# ATSAML21J18BU register map
Vendor: Microchip Technology; Series: SAML21; File version: 0
CPU: CM0+ r0p0, selectable endian, no MPU, no FPU, 2 interrupt priority bits
Registers are 32-bit, read-write, reset 0x0 unless marked. A register's access mark holds for its fields unless they carry their own. Offsets are from the block's base; [hi:lo] are bit positions; {n}, {i} and the like mark numbered series; 'fields as' and 'values as' point back to an identical list.

## MTB — Cortex-M0+ Micro-Trace Buffer
Base 0x41006000; register names take the prefix MTB_
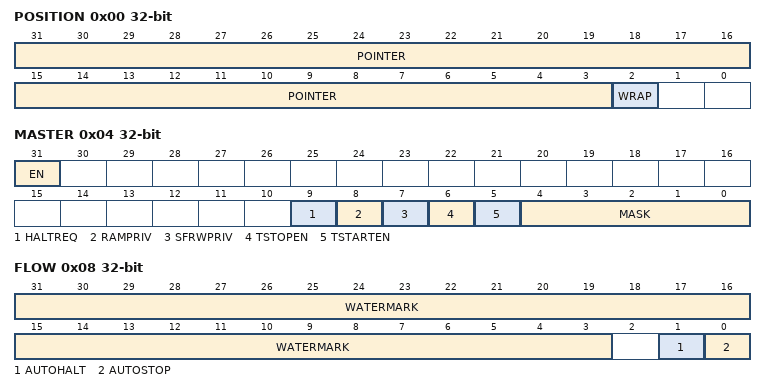
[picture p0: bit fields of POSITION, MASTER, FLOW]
0x00 POSITION — MTB Position
  [31:3] POINTER — Trace Packet Location Pointer
  [2] WRAP — Pointer Value Wraps
0x04 MASTER — MTB Master
  [31] EN — Main Trace Enable
  [9] HALTREQ — Halt Request
  [8] RAMPRIV — SRAM Privilege
  [7] SFRWPRIV — Special Function Register Write Privilege
  [6] TSTOPEN — Trace Stop Input Enable
  [5] TSTARTEN — Trace Start Input Enable
  [4:0] MASK — Maximum Value of the Trace Buffer in SRAM
0x08 FLOW — MTB Flow
  [31:3] WATERMARK — Watermark value
  [1] AUTOHALT — Auto Halt Request
  [0] AUTOSTOP — Auto Stop Tracing
0x0C BASE ro — MTB Base
0xF00 ITCTRL — MTB Integration Mode Control
0xFA0 CLAIMSET — MTB Claim Set
0xFA4 CLAIMCLR — MTB Claim Clear
0xFB0 LOCKACCESS — MTB Lock Access
0xFB4 LOCKSTATUS ro — MTB Lock Status
0xFB8 AUTHSTATUS ro — MTB Authentication Status
0xFBC DEVARCH ro — MTB Device Architecture
0xFC8 DEVID ro — MTB Device Configuration
0xFCC DEVTYPE ro — MTB Device Type
{0xFC0+4i} PID{i} ro (i=4..7) — Peripheral Identification {i}
{0xFE0+4i} PID{i} ro (i=0..3) — Peripheral Identification {i}
{0xFF0+4i} CID{i} ro (i=0..3) — Component Identification {i}

## OPAMP — Operational Amplifier
Base 0x43001800; register names take the prefix OPAMP_
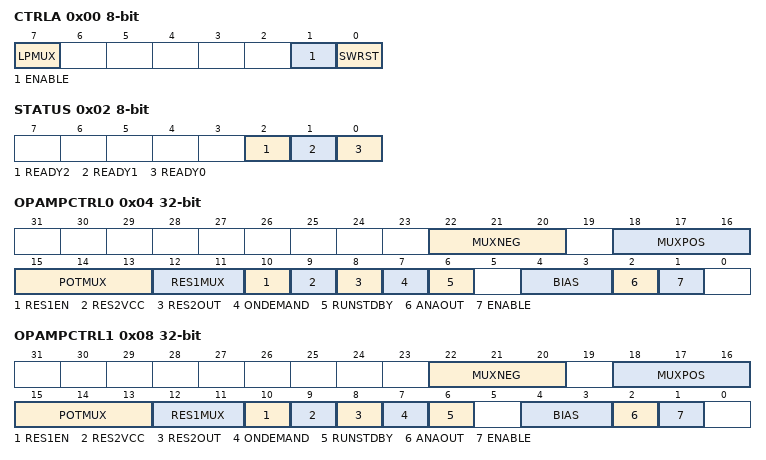
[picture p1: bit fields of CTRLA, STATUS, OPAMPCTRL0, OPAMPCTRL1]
0x00 CTRLA 8-bit — Control A
  [7] LPMUX — Low-Power Mux
  [1] ENABLE
  [0] SWRST — Software Reset
0x02 STATUS 8-bit ro
  [2] READY2 — OPAMP 2 Ready
  [1] READY1 — OPAMP 1 Ready
  [0] READY0 — OPAMP 0 Ready
0x04 OPAMPCTRL0 — OPAMP0 Control
  [22:20] MUXNEG — Negative Input Mux Selection
    0=OA0NEG (Negative I/O pin); 1=OA0TAP (Resistor ladder 0 taps); 2=OA0OUT (OPAMP0 output); 3=DAC (DAC output)
  [18:16] MUXPOS — Positive Input Mux Selection
    0=OA0POS (Positive I/O pin); 1=OA0TAP (Resistor ladder 0 taps); 2=DAC (DAC output); 3=GND (Ground)
  [15:13] POTMUX — Potentiometer Selection
    0=14R_2R (Gain = 0.14); 1=12R_4R (Gain = 0.33); 2=8R_8R (Gain = 1); 3=6R_10R (Gain = 1.67); 4=4R_12R (Gain = 3); 5=3R_13R (Gain = 4.33); 6=2R_14R (Gain = 7); 7=R_15R (Gain = 15)
  [12:11] RES1MUX — Resistor 1 Mux
    0=OAxPOS (Positive inout of OPAMPx); 1=OAxNEG (Negative input of OPAMPx); 2=DAC (DAC output); 3=GND (Ground)
  [10] RES1EN — Resistor 1 Enable
  [9] RES2VCC — Resistor ladder To VCC
  [8] RES2OUT — Resistor ladder To Output
  [7] ONDEMAND — On Demand Control
  [6] RUNSTDBY — Run in Standby
  [4:3] BIAS — Bias Selection
    0=MODE0 (Minimum current consumption, but the slowest mode); 1=MODE1 (Low current consumption, slow speed); 2=MODE2 (High current consumption, fast speed); 3=MODE3 (Maximum current consumption but the fastest mode)
  [2] ANAOUT — Analog Output
  [1] ENABLE — Operational Amplifier Enable
0x08 OPAMPCTRL1 — OPAMP1 Control
  [22:20] MUXNEG — Negative Input Mux Selection
    0=OA1NEG (Negative I/O pin); 1=OA1TAP (Resistor ladder 1 taps); 2=OA1OUT (OPAMP1 output); 3=DAC (DAC output)
  [18:16] MUXPOS — Positive Input Mux Selection
    0=OA1POS (Positive I/O pin); 1=OA1TAP (Resistor ladder 1 taps); 2=OA0OUT (OPAMP0 output); 3=GND (Ground)
  [15:13] POTMUX — Potentiometer Selection
    values as OPAMPCTRL0.POTMUX
  [12:11] RES1MUX — Resistor 1 Mux
    values as OPAMPCTRL0.RES1MUX
  [10] RES1EN — Resistor 1 Enable
  [9] RES2VCC — Resistor ladder To VCC
  [8] RES2OUT — Resistor ladder To Output
  [7] ONDEMAND — On Demand Control
  [6] RUNSTDBY — Run in Standby
  [4:3] BIAS — Bias Selection
    values as OPAMPCTRL0.BIAS
  [2] ANAOUT — Analog Output
  [1] ENABLE — Operational Amplifier Enable
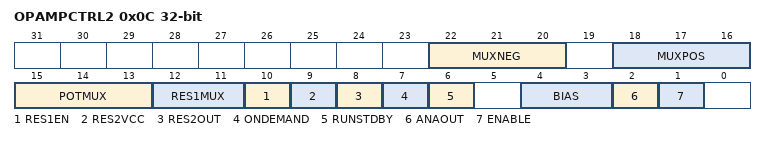
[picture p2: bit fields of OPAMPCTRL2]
0x0C OPAMPCTRL2 — OPAMP2 Control
  [22:20] MUXNEG — Negative Input Mux Selection
    0=OA2NEG (Negative I/O pin); 1=OA2TAP (Resistor ladder 2 taps); 2=OA2OUT (OPAMP2 output); 3=OA0NEG (Negative I/O pin OPA0); 4=OA1NEG (Negative I/O pin OPA1); 5=DAC (DAC output)
  [18:16] MUXPOS — Positive Input Mux Selection
    0=OA2POS (Positive I/O pin); 1=OA2TAP (Resistor ladder 2 taps); 2=OA1OUT (OPAMP1 output); 3=GND (Ground); 4=OA0POS (Positive I/O pin OPA0); 5=OA1POS (Positive I/O pin OPA1); 6=OA0TAP (Resistor ladder 0 taps)
  [15:13] POTMUX — Potentiometer Selection
    values as OPAMPCTRL0.POTMUX
  [12:11] RES1MUX — Resistor 1 Mux
    values as OPAMPCTRL0.RES1MUX
  [10] RES1EN — Resistor 1 Enable
  [9] RES2VCC — Resistor ladder To VCC
  [8] RES2OUT — Resistor ladder To Output
  [7] ONDEMAND — On Demand Control
  [6] RUNSTDBY — Run in Standby
  [4:3] BIAS — Bias Selection
    values as OPAMPCTRL0.BIAS
  [2] ANAOUT — Analog Output
  [1] ENABLE — Operational Amplifier Enable

## Notices in the file
Copyright (c) 2017 Microchip Technology Inc.
SPDX-License-Identifier: Apache-2.0
Licensed under the Apache License, Version 2.0 (the "License");
you may not use this file except in compliance with the License.
You may obtain a copy of the License at
http://www.apache.org/licenses/LICENSE-2.0
Unless required by applicable law or agreed to in writing, software
distributed under the License is distributed on an "AS IS" BASIS,
WITHOUT WARRANTIES OR CONDITIONS OF ANY KIND, either express or implied.
See the License for the specific language governing permissions and
limitations under the License.
